VERSION ""

NS_ :

BS_:

BU_: ENGINE_REPLAY RUL_LISTENER

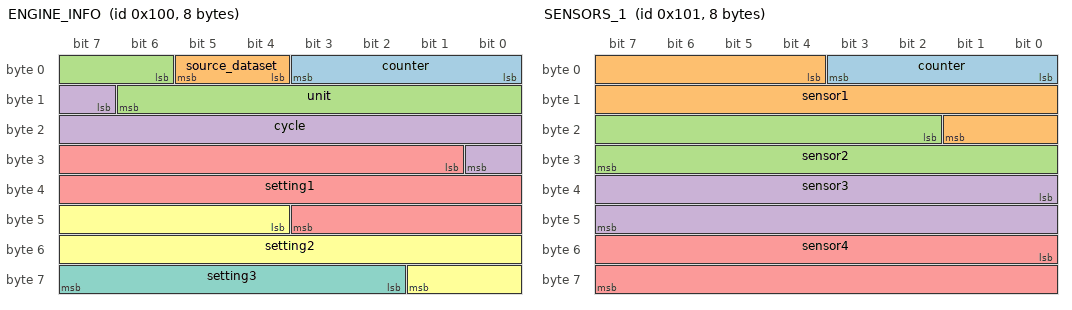
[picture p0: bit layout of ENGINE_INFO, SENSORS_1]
BO_ 256 ENGINE_INFO: 8 ENGINE_REPLAY
 SG_ counter : 0|4@1+ (1,0) [0|15] "" RUL_LISTENER
 SG_ source_dataset : 4|2@1+ (1,0) [0|3] "" RUL_LISTENER
 SG_ unit : 6|9@1+ (1,0) [0|511] "" RUL_LISTENER
 SG_ cycle : 15|10@1+ (1,0) [0|1023] "cycles" RUL_LISTENER
 SG_ setting1 : 25|19@1+ (0.0001,-4.2104) [-4.2104|48.2183] "kft" RUL_LISTENER
 SG_ setting2 : 44|14@1+ (0.0001,-0.0849) [-0.0849|1.5534] "" RUL_LISTENER
 SG_ setting3 : 58|6@1+ (1,56) [56|119] "%" RUL_LISTENER

BO_ 257 SENSORS_1: 8 ENGINE_REPLAY
 SG_ counter : 0|4@1+ (1,0) [0|15] "" RUL_LISTENER
 SG_ sensor1 : 4|14@1+ (0.01,437.63) [437.63|601.46] "degR" RUL_LISTENER
 SG_ sensor2 : 18|14@1+ (0.01,524.51) [524.51|688.34] "degR" RUL_LISTENER
 SG_ sensor3 : 32|16@1+ (0.01,1205.24) [1205.24|1860.59] "degR" RUL_LISTENER
 SG_ sensor4 : 48|16@1+ (0.01,981.99) [981.99|1637.34] "degR" RUL_LISTENER

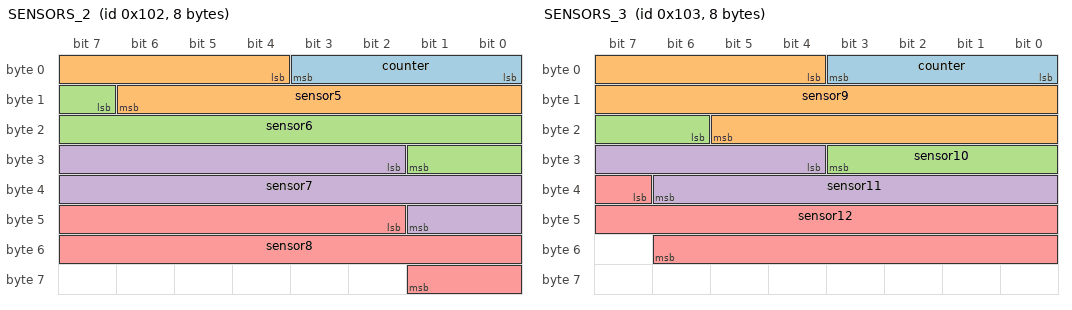
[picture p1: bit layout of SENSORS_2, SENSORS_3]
BO_ 258 SENSORS_2: 8 ENGINE_REPLAY
 SG_ counter : 0|4@1+ (1,0) [0|15] "" RUL_LISTENER
 SG_ sensor5 : 4|11@1+ (0.01,2.83) [2.83|23.3] "psia" RUL_LISTENER
 SG_ sensor6 : 15|11@1+ (0.01,4.07) [4.07|24.54] "psia" RUL_LISTENER
 SG_ sensor7 : 26|16@1+ (0.01,92.7) [92.7|748.05] "psia" RUL_LISTENER
 SG_ sensor8 : 42|16@1+ (0.01,1867.32) [1867.32|2522.67] "rpm" RUL_LISTENER

BO_ 259 SENSORS_3: 8 ENGINE_REPLAY
 SG_ counter : 0|4@1+ (1,0) [0|15] "" RUL_LISTENER
 SG_ sensor9 : 4|18@1+ (0.01,7858.5) [7858.5|10479.93] "rpm" RUL_LISTENER
 SG_ sensor10 : 22|6@1+ (0.01,0.89) [0.89|1.52] "" RUL_LISTENER
 SG_ sensor11 : 28|11@1+ (0.01,34.79) [34.79|55.26] "psia" RUL_LISTENER
 SG_ sensor12 : 39|16@1+ (0.01,87.39) [87.39|742.74] "pps/psi" RUL_LISTENER

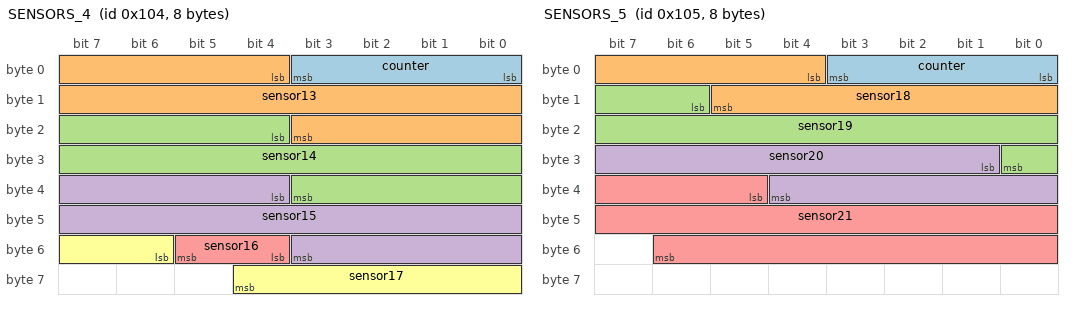
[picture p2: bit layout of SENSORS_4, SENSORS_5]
BO_ 260 SENSORS_4: 8 ENGINE_REPLAY
 SG_ counter : 0|4@1+ (1,0) [0|15] "" RUL_LISTENER
 SG_ sensor13 : 4|16@1+ (0.01,1991.27) [1991.27|2646.62] "rpm" RUL_LISTENER
 SG_ sensor14 : 20|16@1+ (0.01,7800.98) [7800.98|8456.33] "rpm" RUL_LISTENER
 SG_ sensor15 : 36|16@1+ (0.0001,7.8652) [7.8652|14.4187] "" RUL_LISTENER
 SG_ sensor16 : 52|2@1+ (0.01,0.01) [0.01|0.04] "" RUL_LISTENER
 SG_ sensor17 : 54|7@1+ (1,292) [292|419] "" RUL_LISTENER

BO_ 261 SENSORS_5: 8 ENGINE_REPLAY
 SG_ counter : 0|4@1+ (1,0) [0|15] "" RUL_LISTENER
 SG_ sensor18 : 4|10@1+ (1,1867) [1867|2890] "rpm" RUL_LISTENER
 SG_ sensor19 : 14|11@1+ (0.01,83.42) [83.42|103.89] "%" RUL_LISTENER
 SG_ sensor20 : 25|12@1+ (0.01,7.18) [7.18|48.13] "lbm/s" RUL_LISTENER
 SG_ sensor21 : 37|18@1+ (0.0001,4.2165) [4.2165|30.4308] "lbm/s" RUL_LISTENER

CM_ BU_ ENGINE_REPLAY "Replays CMAPSS test data as CAN messages";
CM_ BU_ RUL_LISTENER "Decodes messages and predicts remaining useful life";
CM_ BO_ 256 "Which engine and flight this row is, and the flight conditions";
CM_ SG_ 256 counter "Row counter. Counts 0-15, then starts over at 0. All six messages of one row carry the same value";
CM_ SG_ 256 source_dataset "Which CMAPSS dataset the engine comes from";
CM_ SG_ 256 unit "Engine number within its dataset";
CM_ SG_ 256 cycle "Flight number of this engine";
CM_ SG_ 256 setting1 "Altitude: Flight altitude, thousands of feet";
CM_ SG_ 256 setting2 "Mach: Flight Mach number";
CM_ SG_ 256 setting3 "TRA: Throttle resolver angle, power lever position";
CM_ BO_ 257 "Sensors 1-4";
CM_ SG_ 257 counter "Row counter. Counts 0-15, then starts over at 0. All six messages of one row carry the same value";
CM_ SG_ 257 sensor1 "T2: Total temperature at fan inlet";
CM_ SG_ 257 sensor2 "T24: Total temperature at LPC outlet";
CM_ SG_ 257 sensor3 "T30: Total temperature at HPC outlet";
CM_ SG_ 257 sensor4 "T50: Total temperature at LPT outlet";
CM_ BO_ 258 "Sensors 5-8";
CM_ SG_ 258 counter "Row counter. Counts 0-15, then starts over at 0. All six messages of one row carry the same value";
CM_ SG_ 258 sensor5 "P2: Pressure at fan inlet";
CM_ SG_ 258 sensor6 "P15: Total pressure in bypass duct";
CM_ SG_ 258 sensor7 "P30: Total pressure at HPC outlet";
CM_ SG_ 258 sensor8 "Nf: Physical fan speed";
CM_ BO_ 259 "Sensors 9-12";
CM_ SG_ 259 counter "Row counter. Counts 0-15, then starts over at 0. All six messages of one row carry the same value";
CM_ SG_ 259 sensor9 "Nc: Physical core speed";
CM_ SG_ 259 sensor10 "epr: Engine pressure ratio, P50/P2";
CM_ SG_ 259 sensor11 "Ps30: Static pressure at HPC outlet";
CM_ SG_ 259 sensor12 "phi: Ratio of fuel flow to Ps30";
CM_ BO_ 260 "Sensors 13-17";
CM_ SG_ 260 counter "Row counter. Counts 0-15, then starts over at 0. All six messages of one row carry the same value";
CM_ SG_ 260 sensor13 "NRf: Corrected fan speed";
CM_ SG_ 260 sensor14 "NRc: Corrected core speed";
CM_ SG_ 260 sensor15 "BPR: Bypass ratio";
CM_ SG_ 260 sensor16 "farB: Burner fuel-air ratio";
CM_ SG_ 260 sensor17 "htBleed: Bleed enthalpy";
CM_ BO_ 261 "Sensors 18-21";
CM_ SG_ 261 counter "Row counter. Counts 0-15, then starts over at 0. All six messages of one row carry the same value";
CM_ SG_ 261 sensor18 "Nf_dmd: Demanded fan speed";
CM_ SG_ 261 sensor19 "PCNfR_dmd: Demanded corrected fan speed";
CM_ SG_ 261 sensor20 "W31: HPT coolant bleed";
CM_ SG_ 261 sensor21 "W32: LPT coolant bleed";
VAL_ 256 source_dataset 0 "FD001" 1 "FD002" 2 "FD003" 3 "FD004" ;
